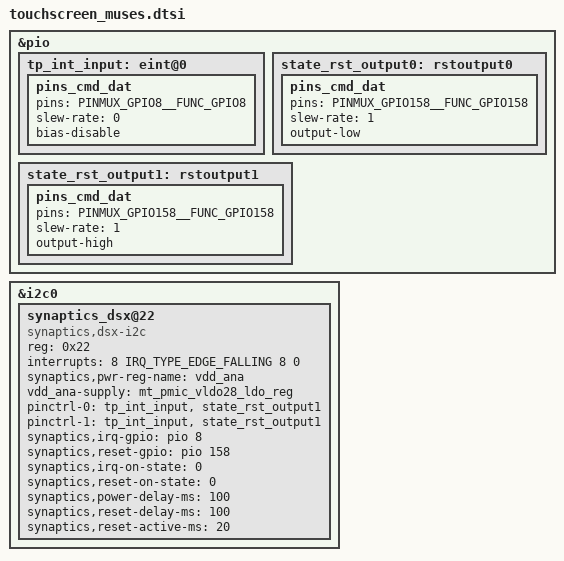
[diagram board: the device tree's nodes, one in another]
&pio {
	tp_int_input: eint@0 {
		pins_cmd_dat {
			pins = <PINMUX_GPIO8__FUNC_GPIO8>;
			slew-rate = <0>;
			bias-disable;
		};
	};

	state_rst_output0: rstoutput0 {
		pins_cmd_dat {
			pins = <PINMUX_GPIO158__FUNC_GPIO158>;
			slew-rate = <1>;
			output-low;
		};
	};

	state_rst_output1: rstoutput1 {
		pins_cmd_dat {
			pins = <PINMUX_GPIO158__FUNC_GPIO158>;
			slew-rate = <1>;
			output-high;
		};
	};

		};



&i2c0 {
	status = "okay";
	synaptics_dsx@22 {
		compatible = "synaptics,dsx-i2c";
		reg = <0x22>;
		interrupts = <8 IRQ_TYPE_EDGE_FALLING 8 0>;
		synaptics,pwr-reg-name = "vdd_ana";
		vdd_ana-supply = <&mt_pmic_vldo28_ldo_reg>;
		pinctrl-names = "pmx_ts_active", "pmx_ts_suspend";
		pinctrl-0 = <&tp_int_input &state_rst_output1>;
		pinctrl-1 = <&tp_int_input &state_rst_output1>;
		synaptics,irq-gpio = <&pio 8 0x00>;
		synaptics,reset-gpio = <&pio 158 0x00>;
		synaptics,irq-on-state = <0>;
		synaptics,reset-on-state = <0>;
		synaptics,power-delay-ms = <100>;
		synaptics,reset-delay-ms = <100>;
		synaptics,reset-active-ms = <20>;
	};
};

